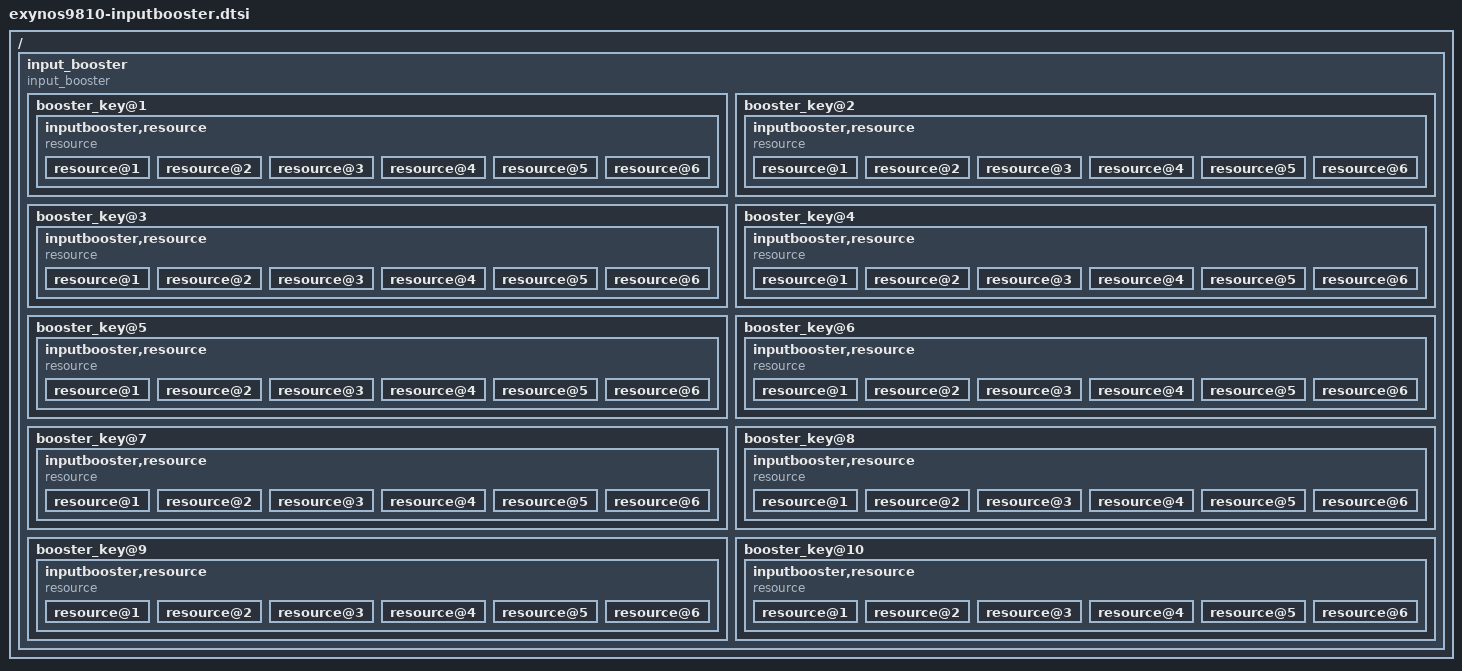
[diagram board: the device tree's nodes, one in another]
/ {
	input_booster {
		status = "okay";
		compatible = "input_booster";
		max_resource_count = [37 00];
		#address-cells = <1>;
		#size-cells = <0>;
		ib_release_values = "0,0,0,0,0,0,0";

		booster_key@1 {
			input_booster,label = "key";
			input_booster,type = <0>;	/* BOOSTER_DEVICE_KEY */
			/* Time table */
			input_booster,head_time = <500>;
			input_booster,tail_time = <500>;

			/* Frequency table */
			/* for level	:	Head, Tail */
			inputbooster,resource {
				compatible = "resource";

				resource@1 {
					resource,label = "cluster1";
					resource,value = <1066000 0>;
				};

				resource@2 {
					resource,label = "cluster0";
					resource,value = <0 0>;
				};

				resource@3 {
					resource,label = "mif";
					resource,value = <0 0>;
				};

				resource@4 {
					resource,label = "int";
					resource,value = <0 0>;
				};

				resource@5 {
					resource,label = "hmp";
					resource,value = <1 0>;
				};

				resource@6 {
					resource,label = "ucc";
					resource,value = <1 0>;
				};
			};
		};
		booster_key@2 {
			input_booster,label = "touchkey";
			input_booster,type = <1>;	/* BOOSTER_DEVICE_TOUCHKEY */
			/* Time table */
			input_booster,head_time = <0>;
			input_booster,tail_time = <200>;

			/* Frequency table */
			/* for level	:	Head, Tail */
			inputbooster,resource {
				compatible = "resource";

				resource@1 {
					resource,label = "cluster1";
					resource,value = <1066000 0>;
				};

				resource@2 {
					resource,label = "cluster0";
					resource,value = <0 0>;
				};

				resource@3 {
					resource,label = "mif";
					resource,value = <0 0>;
				};

				resource@4 {
					resource,label = "int";
					resource,value = <0 0>;
				};

				resource@5 {
					resource,label = "hmp";
					resource,value = <1 0>;
				};

				resource@6 {
					resource,label = "ucc";
					resource,value = <1 0>;
				};
			};
		};
		booster_key@3 {
			input_booster,label = "touch";
			input_booster,type = <2>;	/* BOOSTER_DEVICE_TOUCH */
			/* Time table */
			input_booster,head_time = <130>;
			input_booster,tail_time = <500>;

			/* Frequency table */
			/* for level	:	Head, Tail */
			inputbooster,resource {
				compatible = "resource";

				resource@1 {
					resource,label = "cluster1";
					resource,value = <1066000 858000>;
				};

				resource@2 {
					resource,label = "cluster0";
					resource,value = <832000 832000>;
				};

				resource@3 {
					resource,label = "mif";
					resource,value = <0 0>;
				};

				resource@4 {
					resource,label = "int";
					resource,value = <0 0>;
				};

				resource@5 {
					resource,label = "hmp";
					resource,value = <1 1>;
				};

				resource@6 {
					resource,label = "ucc";
					resource,value = <1 1>;
				};
			};
		};
		booster_key@4 { // Input Booster +
			input_booster,label = "multitouch";
			input_booster,type = <3>;	/* BOOSTER_DEVICE_MULTITOUCH */
			/* Time table */
			input_booster,head_time = <1000>;
			input_booster,tail_time = <500>;

			/* Frequency table */
			/* for level	:	Head, Tail */
			inputbooster,resource {
				compatible = "resource";

				resource@1 {
					resource,label = "cluster1";
					resource,value = <1066000 858000>;
				};

				resource@2 {
					resource,label = "cluster0";
					resource,value = <832000 832000>;
				};

				resource@3 {
					resource,label = "mif";
					resource,value = <0 0>;
				};

				resource@4 {
					resource,label = "int";
					resource,value = <0 0>;
				};

				resource@5 {
					resource,label = "hmp";
					resource,value = <1 1>;
				};

				resource@6 {
					resource,label = "ucc";
					resource,value = <1 1>;
				};
			};
		};
		booster_key@5 {
			input_booster,label = "keyboard";
			input_booster,type = <4>;	/* BOOSTER_DEVICE_KEYBOARD */
			/* Time table */
			input_booster,head_time = <130>;
			input_booster,tail_time = <0>;

			/* Frequency table */
			/* for level	:	Head, Tail */
			inputbooster,resource {
				compatible = "resource";

				resource@1 {
					resource,label = "cluster1";
					resource,value = <1066000 858000>;
				};

				resource@2 {
					resource,label = "cluster0";
					resource,value = <832000 832000>;
				};

				resource@3 {
					resource,label = "mif";
					resource,value = <0 0>;
				};

				resource@4 {
					resource,label = "int";
					resource,value = <0 0>;
				};

				resource@5 {
					resource,label = "hmp";
					resource,value = <1 1>;
				};

				resource@6 {
					resource,label = "ucc";
					resource,value = <1 1>;
				};
			};
		};
		booster_key@6 {
			input_booster,label = "mouse";
			input_booster,type = <5>;	/* BOOSTER_DEVICE_MOUSE */
			/* Time table */
			input_booster,head_time = <130>;
			input_booster,tail_time = <500>;

			/* Frequency table */
			/* for level	:	Head, Tail */
			inputbooster,resource {
				compatible = "resource";

				resource@1 {
					resource,label = "cluster1";
					resource,value = <1066000 858000>;
				};

				resource@2 {
					resource,label = "cluster0";
					resource,value = <832000 832000>;
				};

				resource@3 {
					resource,label = "mif";
					resource,value = <0 0>;
				};

				resource@4 {
					resource,label = "int";
					resource,value = <0 0>;
				};

				resource@5 {
					resource,label = "hmp";
					resource,value = <1 1>;
				};

				resource@6 {
					resource,label = "ucc";
					resource,value = <1 1>;
				};
			};
		};
		booster_key@7 {
			input_booster,label = "mouse_wheel";
			input_booster,type = <6>;	/* BOOSTER_DEVICE_MOUSE */
			/* Time table */
			input_booster,head_time = <130>;
			input_booster,tail_time = <0>;

			/* Frequency table */
			/* for level	:	Head, Tail */
			inputbooster,resource {
				compatible = "resource";

				resource@1 {
					resource,label = "cluster1";
					resource,value = <1066000 858000>;
				};

				resource@2 {
					resource,label = "cluster0";
					resource,value = <832000 832000>;
				};

				resource@3 {
					resource,label = "mif";
					resource,value = <0 0>;
				};

				resource@4 {
					resource,label = "int";
					resource,value = <0 0>;
				};

				resource@5 {
					resource,label = "hmp";
					resource,value = <1 1>;
				};

				resource@6 {
					resource,label = "ucc";
					resource,value = <1 1>;
				};
			};
		};
		booster_key@8 {
			input_booster,label = "pen_hover";
			input_booster,type = <7>;	/* BOOSTER_DEVICE_MOUSE */
			/* Time table */
			input_booster,head_time = <130>;
			input_booster,tail_time = <500>;

			/* Frequency table */
			/* for level	:	Head, Tail */
			inputbooster,resource {
				compatible = "resource";

				resource@1 {
					resource,label = "cluster1";
					resource,value = <1066000 858000>;
				};

				resource@2 {
					resource,label = "cluster0";
					resource,value = <832000 832000>;
				};

				resource@3 {
					resource,label = "mif";
					resource,value = <0 0>;
				};

				resource@4 {
					resource,label = "int";
					resource,value = <0 0>;
				};

				resource@5 {
					resource,label = "hmp";
					resource,value = <1 1>;
				};

				resource@6 {
					resource,label = "ucc";
					resource,value = <1 1>;
				};
			};
		};
		booster_key@9 {
			input_booster,label = "pen";
			input_booster,type = <8>;	/* BOOSTER_DEVICE_MOUSE */
			/* Time table */
			input_booster,head_time = <200>;
			input_booster,tail_time = <600>;

			/* Frequency table */
			/* for level	:	Head, Tail */
			inputbooster,resource {
				compatible = "resource";

				resource@1 {
					resource,label = "cluster1";
					resource,value = <1170000 858000>;
				};

				resource@2 {
					resource,label = "cluster0";
					resource,value = <832000 832000>;
				};

				resource@3 {
					resource,label = "mif";
					resource,value = <0 0>;
				};

				resource@4 {
					resource,label = "int";
					resource,value = <0 0>;
				};

				resource@5 {
					resource,label = "hmp";
					resource,value = <1 1>;
				};

				resource@6 {
					resource,label = "ucc";
					resource,value = <1 1>;
				};
			};
		};
		booster_key@10 {
			input_booster,label = "key_two";
			input_booster,type = <9>;	/* BOOSTER_DEVICE_KEY */
			/* Time table */
			input_booster,head_time = <700>;
			input_booster,tail_time = <700>;

			/* Frequency table */
			/* for level	:	Head, Tail */
			inputbooster,resource {
				compatible = "resource";

				resource@1 {
					resource,label = "cluster1";
					resource,value = <1469000 0>;
				};

				resource@2 {
					resource,label = "cluster0";
					resource,value = <1053000 0>;
				};

				resource@3 {
					resource,label = "mif";
					resource,value = <0 0>;
				};

				resource@4 {
					resource,label = "int";
					resource,value = <0 0>;
				};

				resource@5 {
					resource,label = "hmp";
					resource,value = <1 1>;
				};

				resource@6 {
					resource,label = "ucc";
					resource,value = <1 1>;
				};
			};
		}; // Input Booster -
		/* If you need to add new key type, add it this position */
	};
};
